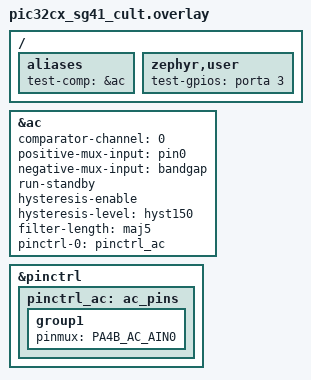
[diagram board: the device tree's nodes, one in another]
/*
 * Copyright (c) 2025 Microchip Technology Inc.
 *
 * SPDX-License-Identifier: Apache-2.0
 */

/* connect the PA04 to PA03 for the test */

/ {
	aliases {
		test-comp = &ac;
	};

	zephyr,user {
		test-gpios = <&porta 3 GPIO_ACTIVE_HIGH>;
	};
};

&ac {
	comparator-channel = <0>;
	positive-mux-input = "pin0";
	negative-mux-input = "bandgap";
	run-standby;
	hysteresis-enable;
	hysteresis-level = "hyst150";
	filter-length = "maj5";
	// single-shot-mode;

	/* Assign pinctrl for PA04 */
	pinctrl-0 = <&pinctrl_ac>;
	pinctrl-names = "default";

	status = "okay";
};

&pinctrl {
	pinctrl_ac: ac_pins {
		group1 {
			pinmux = <PA4B_AC_AIN0>;
		};
	};
};
